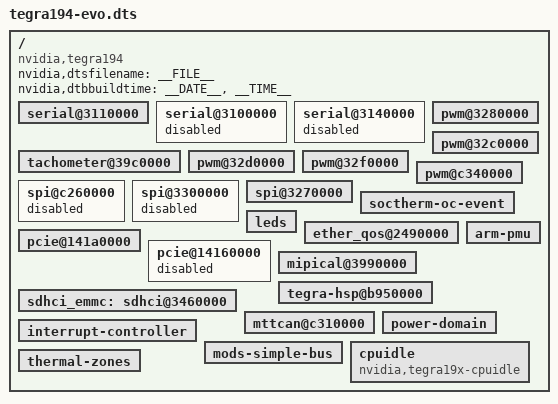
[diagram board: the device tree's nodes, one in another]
/*
 * Top level DTS file for CVM:P3668-0001 and CVB:P3509-0000.
 *
 * Copyright (c) 2019-2020, NVIDIA CORPORATION.  All rights reserved.
 *
 * This program is free software; you can redistribute it and/or modify
 * it under the terms of the GNU General Public License as published by
 * the Free Software Foundation; version 2 of the License.
 *
 * This program is distributed in the hope that it will be useful, but WITHOUT
 * ANY WARRANTY; without even the implied warranty of MERCHANTABILITY or
 * FITNESS FOR A PARTICULAR PURPOSE.  See the GNU General Public License for
 * more details.
 */

/dts-v1/;
#include "common/tegra194-common.dtsi"
#include "common/tegra194-base.dtsi"
#include "common/tegra194-avt-camera-csi.dtsi"


/ {
  nvidia,dtsfilename = __FILE__;
  nvidia,dtbbuildtime = __DATE__, __TIME__;

  compatible = "nvidia,tegra194";

  /* Serial Ports */
  serial@3110000 {
    status = "okay";
  };

  serial@3100000 {
    status = "disabled";
  };

  serial@3140000 {
    status = "disabled";
  };

  tachometer@39c0000 {
    status = "okay";
  };

  /* PWM */
  pwm@3280000 {
    status = "okay";
  };

  pwm@32c0000 {
    status = "okay";
  };

  pwm@32d0000 {
    status = "okay";
  };

  pwm@32f0000 {
    status = "okay";
  };

  pwm@c340000 {
    status = "okay";
  };

  spi@c260000 {
    status = "disabled";
  };

  spi@3300000 {
    status = "disabled";
  };

  /* QSPI flash S25FS128SAGNFI103 is controlled by qspi0 */
  spi@3270000 {
    status = "okay";
  };

  soctherm-oc-event {
    status = "okay";
  };

  leds {
    status = "okay";
  };

  /* Ethernet */
  ether_qos@2490000 {
    status = "okay";
  };


  /* 4 Lanes - NVME SSD */
  pcie@141a0000 {
    status = "okay";
  };

  /* 1 Lane - Expansion Connector. Not needed right now */
  pcie@14160000 {
    status = "disabled";
  };

  mipical@3990000 {
    status = "okay";
  };

  tegra-hsp@b950000 {
    status = "okay";
  };

  /* EMMC on Production Jetson NX */
  sdhci_emmc: sdhci@3460000 {
    status = "okay";
  };

  /* CAN Interface */
  mttcan@c310000 {
    status = "okay";
  };

  /* Below node can be moved to cvb to make decision about enabling/disabling */
  arm-pmu {
    status = "okay";
  };

  power-domain {
    status = "okay";
  };

  interrupt-controller {
    status = "okay";
  };

  mods-simple-bus {
    status = "okay";
  };

  cpuidle {
    compatible = "nvidia,tegra19x-cpuidle";
    status = "okay";
  };

  thermal-zones {
    status = "okay";
  };
};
